# Port_J_4 register map
Vendor: Texas Instruments
Peripheral module from a debugger description file (folder msp430).
Registers are 16-bit, read-write, reset 0x0 unless marked. A register's access mark holds for its fields unless they carry their own. Offsets are as the file gives them; lines under a group give offsets from that group; [hi:lo] are bit positions; {n}, {i} and the like mark numbered series; 'fields as' and 'values as' point back to an identical list; <NAME> marks a mode.

## Port_J
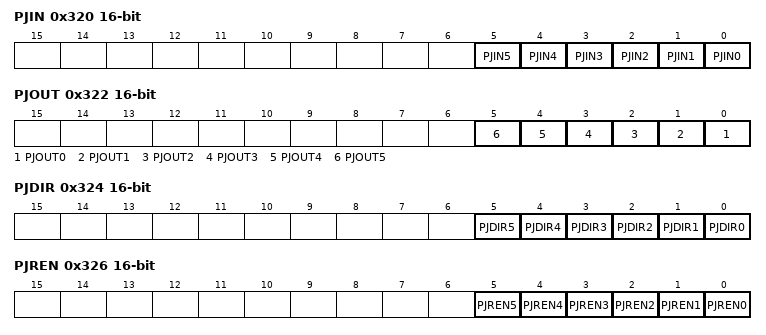
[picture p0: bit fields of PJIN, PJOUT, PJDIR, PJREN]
0x320 PJIN — Port J Input
  [n] PJIN{n} (n=0..5)
0x322 PJOUT — Port J Output
  [n] PJOUT{n} (n=0..5)
0x324 PJDIR — Port J Direction
  [n] PJDIR{n} (n=0..5)
0x326 PJREN — Port J Resistor Enable
  [n] PJREN{n} (n=0..5)
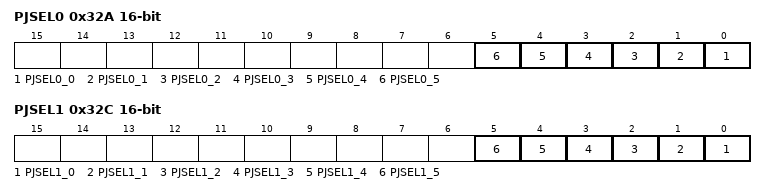
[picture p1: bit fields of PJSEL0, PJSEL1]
0x32A PJSEL0 — Port J Selection 0
  [n] PJSEL0_{n} (n=0..5)
0x32C PJSEL1 — Port J Selection 1
  [n] PJSEL1_{n} (n=0..5)
0x336 PJSELC access not given reset not defined — Port J Complement Selection
